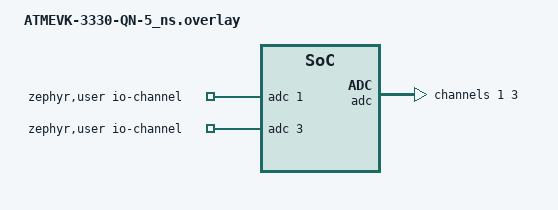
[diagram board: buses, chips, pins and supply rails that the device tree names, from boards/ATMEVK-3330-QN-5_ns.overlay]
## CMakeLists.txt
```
# SPDX-License-Identifier: Apache-2.0

cmake_minimum_required(VERSION 3.28.0)

find_package(Zephyr REQUIRED HINTS $ENV{ZEPHYR_BASE})
project(adc_api)

target_sources(app PRIVATE src/channels.c)
target_sources_ifdef(CONFIG_TEST_ADC_BASIC app PRIVATE src/main.c src/test_adc.c)
target_sources_ifdef(CONFIG_TEST_ADC_ERROR_CASES app PRIVATE src/test_error_cases.c)
target_sources_ifdef(CONFIG_TEST_ADC_ACCURACY_REF app PRIVATE src/test_accuracy_ref.c)
target_sources_ifdef(CONFIG_TEST_ADC_ACCURACY_DAC app PRIVATE src/test_accuracy_dac.c)
```

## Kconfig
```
# ADC API test configuration options

# Copyright (c) 2024 STMicroelectronics
# SPDX-License-Identifier: Apache-2.0

mainmenu "ADC API Test"

source "Kconfig.zephyr"

config ADC_API_SAMPLE_INTERVAL_US
	int "Interval between repeated samples in us"
	default 0

config ADC_32_BITS_DATA
	bool "ADC data is 32-bits long"

config TEST_ADC_CALIBRATE_REQUIRED
	bool "Require calibrate field in ADC test"
	default y if DT_HAS_RENESAS_RA_ADC16_ENABLED
```

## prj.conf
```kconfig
CONFIG_ZTEST=y

CONFIG_ADC=y
CONFIG_ADC_ASYNC=y
CONFIG_ADC_LOG_LEVEL_INF=y
CONFIG_HEAP_MEM_POOL_SIZE=1024
CONFIG_TEST_USERSPACE=y
```

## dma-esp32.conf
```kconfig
#
# Copyright (c) 2024-2025 Espressif Systems (Shanghai) Co., Ltd.
#
# SPDX-License-Identifier: Apache-2.0
#

CONFIG_TEST_USERSPACE=n
CONFIG_ADC_ESP32_DMA=y
CONFIG_HEAP_MEM_POOL_SIZE=16384
```

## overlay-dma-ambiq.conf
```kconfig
CONFIG_ADC_AMBIQ_DMA=y
CONFIG_ADC_ASYNC=n
CONFIG_MAIN_STACK_SIZE=40960
#Reduce the minimum number of samples only for test.
CONFIG_ADC_AMBIQ_DMA_MIN_SAMPLES=2
```

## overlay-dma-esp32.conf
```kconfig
#
# Copyright (c) 2024 Espressif Systems (Shanghai) Co., Ltd.
#
# SPDX-License-Identifier: Apache-2.0
#

CONFIG_TEST_USERSPACE=n
CONFIG_DMA=y
CONFIG_ADC_ESP32_DMA=y
CONFIG_HEAP_MEM_POOL_SIZE=16384
```

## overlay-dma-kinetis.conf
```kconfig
#
# Copyright (c) 2020, NXP
#
# SPDX-License-Identifier: Apache-2.0
#

CONFIG_TEST_USERSPACE=n
CONFIG_ADC_MCUX_ADC16_ENABLE_EDMA=y
CONFIG_ADC_MCUX_ADC16_HW_TRIGGER=y
CONFIG_COUNTER=y
CONFIG_ADC_ASYNC=y
CONFIG_DMA=y
CONFIG_ADC_API_SAMPLE_INTERVAL_US=30000
```

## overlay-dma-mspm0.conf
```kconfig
# SPDX-FileCopyrightText: 2026 Texas Instruments Incorporated
# SPDX-License-Identifier: Apache-2.0

CONFIG_ADC_MSPM0_ADC12_DMA=y
```

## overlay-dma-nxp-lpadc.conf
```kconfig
# Copyright 2025 NXP
# SPDX-License-Identifier: Apache-2.0

CONFIG_ADC_MCUX_LPADC_DMA_DRIVEN=y
CONFIG_TEST_USERSPACE=n
```

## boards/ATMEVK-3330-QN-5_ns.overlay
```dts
/*
 * Copyright (c) 2023 Atmosic
 *
 * SPDX-License-Identifier: Apache-2.0
 */

/ {
	zephyr,user {
		io-channels = <&adc 1>, <&adc 3>;
	};
};

&adc {
	#address-cells = <1>;
	#size-cells = <0>;

	channel@1 {
		reg = <1>;
		zephyr,gain = "ADC_GAIN_1_4";
		zephyr,reference = "ADC_REF_INTERNAL";
		zephyr,acquisition-time = <ADC_ACQ_TIME_DEFAULT>;
		zephyr,resolution = <11>;
	};

	channel@3 {
		reg = <3>;
		zephyr,gain = "ADC_GAIN_1_2";
		zephyr,reference = "ADC_REF_INTERNAL";
		zephyr,acquisition-time = <ADC_ACQ_TIME_DEFAULT>;
		zephyr,resolution = <11>;
	};
};
```

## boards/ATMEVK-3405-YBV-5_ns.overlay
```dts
/*
 * Copyright (c) 2025 Atmosic
 *
 * SPDX-License-Identifier: Apache-2.0
 */

/ {
	zephyr,user {
		io-channels = <&adc 3>, <&adc 4>;
	};
};

&adc {
	#address-cells = <1>;
	#size-cells = <0>;

	channel@1 {
		reg = <1>;
		zephyr,gain = "ADC_GAIN_1_4";
		zephyr,reference = "ADC_REF_INTERNAL";
		zephyr,acquisition-time = <ADC_ACQ_TIME_DEFAULT>;
		zephyr,resolution = <16>;
	};

	channel@2 {
		reg = <2>;
		zephyr,gain = "ADC_GAIN_1_4";
		zephyr,reference = "ADC_REF_INTERNAL";
		zephyr,acquisition-time = <ADC_ACQ_TIME_DEFAULT>;
		zephyr,resolution = <16>;
	};

	channel@3 {
		reg = <3>;
		zephyr,gain = "ADC_GAIN_1_2";
		zephyr,reference = "ADC_REF_INTERNAL";
		zephyr,acquisition-time = <ADC_ACQ_TIME_DEFAULT>;
		zephyr,resolution = <16>;
	};

	channel@4 {
		reg = <4>;
		zephyr,gain = "ADC_GAIN_1";
		zephyr,reference = "ADC_REF_INTERNAL";
		zephyr,acquisition-time = <ADC_ACQ_TIME_DEFAULT>;
		zephyr,resolution = <16>;
	};

	channel@5 {
		reg = <5>;
		zephyr,gain = "ADC_GAIN_1_4";
		zephyr,reference = "ADC_REF_INTERNAL";
		zephyr,acquisition-time = <ADC_ACQ_TIME_DEFAULT>;
		zephyr,resolution = <16>;
	};

	channel@6 {
		reg = <6>;
		zephyr,gain = "ADC_GAIN_1_4";
		zephyr,reference = "ADC_REF_INTERNAL";
		zephyr,acquisition-time = <ADC_ACQ_TIME_DEFAULT>;
		zephyr,resolution = <16>;
	};

	channel@7 {
		reg = <7>;
		zephyr,gain = "ADC_GAIN_1_4";
		zephyr,reference = "ADC_REF_INTERNAL";
		zephyr,acquisition-time = <ADC_ACQ_TIME_DEFAULT>;
		zephyr,resolution = <16>;
	};

	channel@8 {
		reg = <8>;
		zephyr,gain = "ADC_GAIN_1_4";
		zephyr,reference = "ADC_REF_INTERNAL";
		zephyr,acquisition-time = <ADC_ACQ_TIME_DEFAULT>;
		zephyr,resolution = <16>;
	};

	channel@9 {
		reg = <9>;
		zephyr,gain = "ADC_GAIN_1_4";
		zephyr,reference = "ADC_REF_INTERNAL";
		zephyr,acquisition-time = <ADC_ACQ_TIME_DEFAULT>;
		zephyr,resolution = <16>;
	};

	channel@a {
		reg = <10>;
		zephyr,gain = "ADC_GAIN_1_4";
		zephyr,reference = "ADC_REF_INTERNAL";
		zephyr,acquisition-time = <ADC_ACQ_TIME_DEFAULT>;
		zephyr,resolution = <16>;
	};

	channel@b {
		reg = <11>;
		zephyr,gain = "ADC_GAIN_1_2";
		zephyr,reference = "ADC_REF_INTERNAL";
		zephyr,acquisition-time = <ADC_ACQ_TIME_DEFAULT>;
		zephyr,resolution = <16>;
	};
};
```

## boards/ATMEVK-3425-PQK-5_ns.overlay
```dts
/*
 * Copyright (c) 2023 Atmosic
 *
 * SPDX-License-Identifier: Apache-2.0
 */

/ {
	zephyr,user {
		io-channels = <&adc 3>, <&adc 4>;
	};
};

&adc {
	#address-cells = <1>;
	#size-cells = <0>;

	channel@1 {
		reg = <1>;
		zephyr,gain = "ADC_GAIN_1_4";
		zephyr,reference = "ADC_REF_INTERNAL";
		zephyr,acquisition-time = <ADC_ACQ_TIME_DEFAULT>;
		zephyr,resolution = <16>;
	};

	channel@2 {
		reg = <2>;
		zephyr,gain = "ADC_GAIN_1_4";
		zephyr,reference = "ADC_REF_INTERNAL";
		zephyr,acquisition-time = <ADC_ACQ_TIME_DEFAULT>;
		zephyr,resolution = <16>;
	};

	channel@3 {
		reg = <3>;
		zephyr,gain = "ADC_GAIN_1_2";
		zephyr,reference = "ADC_REF_INTERNAL";
		zephyr,acquisition-time = <ADC_ACQ_TIME_DEFAULT>;
		zephyr,resolution = <16>;
	};

	channel@4 {
		reg = <4>;
		zephyr,gain = "ADC_GAIN_1";
		zephyr,reference = "ADC_REF_INTERNAL";
		zephyr,acquisition-time = <ADC_ACQ_TIME_DEFAULT>;
		zephyr,resolution = <16>;
	};

	channel@5 {
		reg = <5>;
		zephyr,gain = "ADC_GAIN_1_4";
		zephyr,reference = "ADC_REF_INTERNAL";
		zephyr,acquisition-time = <ADC_ACQ_TIME_DEFAULT>;
		zephyr,resolution = <16>;
	};

	channel@6 {
		reg = <6>;
		zephyr,gain = "ADC_GAIN_1_4";
		zephyr,reference = "ADC_REF_INTERNAL";
		zephyr,acquisition-time = <ADC_ACQ_TIME_DEFAULT>;
		zephyr,resolution = <16>;
	};

	channel@7 {
		reg = <7>;
		zephyr,gain = "ADC_GAIN_1_4";
		zephyr,reference = "ADC_REF_INTERNAL";
		zephyr,acquisition-time = <ADC_ACQ_TIME_DEFAULT>;
		zephyr,resolution = <16>;
	};

	channel@8 {
		reg = <8>;
		zephyr,gain = "ADC_GAIN_1_4";
		zephyr,reference = "ADC_REF_INTERNAL";
		zephyr,acquisition-time = <ADC_ACQ_TIME_DEFAULT>;
		zephyr,resolution = <16>;
	};

	channel@9 {
		reg = <9>;
		zephyr,gain = "ADC_GAIN_1_4";
		zephyr,reference = "ADC_REF_INTERNAL";
		zephyr,acquisition-time = <ADC_ACQ_TIME_DEFAULT>;
		zephyr,resolution = <16>;
	};

	channel@a {
		reg = <10>;
		zephyr,gain = "ADC_GAIN_1_4";
		zephyr,reference = "ADC_REF_INTERNAL";
		zephyr,acquisition-time = <ADC_ACQ_TIME_DEFAULT>;
		zephyr,resolution = <16>;
	};

	channel@b {
		reg = <11>;
		zephyr,gain = "ADC_GAIN_1_2";
		zephyr,reference = "ADC_REF_INTERNAL";
		zephyr,acquisition-time = <ADC_ACQ_TIME_DEFAULT>;
		zephyr,resolution = <16>;
	};
};
```

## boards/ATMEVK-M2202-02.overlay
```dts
/*
 * Copyright (c) 2023 Atmosic
 *
 * SPDX-License-Identifier: Apache-2.0
 */

/ {
	zephyr,user {
		io-channels = <&adc 0>, <&adc 2>;
	};
};

&adc {
	#address-cells = <1>;
	#size-cells = <0>;

	channel@0 {
		reg = <0>;
		zephyr,gain = "ADC_GAIN_1";
		zephyr,reference = "ADC_REF_INTERNAL";
		zephyr,acquisition-time = <ADC_ACQ_TIME_DEFAULT>;
		zephyr,resolution = <10>;
	};

	channel@2 {
		reg = <2>;
		zephyr,gain = "ADC_GAIN_1";
		zephyr,reference = "ADC_REF_INTERNAL";
		zephyr,acquisition-time = <ADC_ACQ_TIME_DEFAULT>;
		zephyr,resolution = <10>;
	};
};
```

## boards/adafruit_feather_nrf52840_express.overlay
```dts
/*
 * SPDX-License-Identifier: Apache-2.0
 *
 * Copyright (c) 2023 Benjamin Björnsson <benjamin.bjornsson@gmail.com>
 */

#include "nordic,nrf-saadc-common.dtsi"
```

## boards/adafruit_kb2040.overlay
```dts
/*
 * Copyright (c) 2023 Benjamin Björnsson <benjamin.bjornsson@gmail.com>
 *
 * SPDX-License-Identifier: Apache-2.0
 */

#include <zephyr/dt-bindings/adc/adc.h>

/ {
	zephyr,user {
		io-channels = <&adc 0>, <&adc 1>;
	};
};

&adc {
	#address-cells = <1>;
	#size-cells = <0>;

	channel@0 {
		reg = <0>;
		zephyr,gain = "ADC_GAIN_1";
		zephyr,reference = "ADC_REF_INTERNAL";
		zephyr,acquisition-time = <ADC_ACQ_TIME_DEFAULT>;
		zephyr,resolution = <12>;
	};

	channel@1 {
		reg = <1>;
		zephyr,gain = "ADC_GAIN_1";
		zephyr,reference = "ADC_REF_INTERNAL";
		zephyr,acquisition-time = <ADC_ACQ_TIME_DEFAULT>;
		zephyr,resolution = <12>;
	};
};
```

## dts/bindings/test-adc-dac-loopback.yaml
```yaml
# SPDX-FileCopyrightText: Copyright The Zephyr Project Contributors
# SPDX-License-Identifier: Apache-2.0

description: |
  A DAC output of the board wired to one of its ADC channels, for the
  accuracy test of tests/drivers/adc/adc_api.

compatible: "test-adc-dac-loopback"

include: base.yaml

properties:
  io-channels:
    type: phandle-array
    required: true
    description: The ADC channel the DAC output is wired to.

  dac:
    type: phandle
    required: true
    description: The DAC controller.

  dac-channel-id:
    type: int
    required: true
    description: The DAC channel driving the output.

  dac-resolution:
    type: int
    required: true
    description: The resolution the DAC channel is set up with, in bits.
```

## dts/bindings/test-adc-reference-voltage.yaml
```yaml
# SPDX-FileCopyrightText: Copyright The Zephyr Project Contributors
# SPDX-License-Identifier: Apache-2.0

description: |
  A known voltage wired to an ADC channel of the board, for the accuracy
  test of tests/drivers/adc/adc_api.

compatible: "test-adc-reference-voltage"

include: base.yaml

properties:
  io-channels:
    type: phandle-array
    required: true
    description: The ADC channel the reference voltage is wired to.

  reference-mv:
    type: int
    required: true
    description: The reference voltage, in millivolts.

  expected-accuracy:
    type: int
    required: true
    description: The largest acceptable difference from the reference, in millivolts.
```

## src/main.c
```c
/*
 * Copyright (c) 2018 Nordic Semiconductor ASA
 * Copyright (c) 2016 Intel Corporation
 *
 * SPDX-License-Identifier: Apache-2.0
 */


#include <zephyr/kernel.h>
#include <zephyr/ztest.h>

#include "adc_test.h"

extern struct k_poll_signal async_sig;

void *adc_basic_setup(void)
{
	k_object_access_grant(get_adc_device(), k_current_get());
#ifdef CONFIG_ADC_ASYNC
	k_object_access_grant(&async_sig, k_current_get());
	k_poll_signal_init(&async_sig);
	k_thread_system_pool_assign(k_current_get());
#endif

	return NULL;
}

ZTEST_SUITE(adc_basic, NULL, adc_basic_setup, NULL, NULL, NULL);
```

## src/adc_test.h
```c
/*
 * SPDX-FileCopyrightText: Copyright The Zephyr Project Contributors
 * SPDX-License-Identifier: Apache-2.0
 */

#ifndef TESTS_DRIVERS_ADC_ADC_API_SRC_ADC_TEST_H_
#define TESTS_DRIVERS_ADC_ADC_API_SRC_ADC_TEST_H_

#include <zephyr/drivers/adc.h>

#define ADC_TEST_COUNT_ONE(node_id) + 1

/*
 * Number of channels the board makes available to the tests: the io-channels
 * of the zephyr,user node when present, otherwise every channel node of an
 * enabled ADC controller.
 */
#if DT_NODE_HAS_PROP(DT_PATH(zephyr_user), io_channels)
#define ADC_TEST_CHANNEL_COUNT DT_PROP_LEN(DT_PATH(zephyr_user), io_channels)
#else
#define ADC_TEST_CHANNEL_COUNT (0 ADC_DT_FOREACH_CHANNEL_NODE(ADC_TEST_COUNT_ONE))
#endif

BUILD_ASSERT(ADC_TEST_CHANNEL_COUNT > 0, "No ADC channel described in devicetree");

/* The channels, the first one being the one the tests exercise. */
extern const struct adc_dt_spec adc_test_channels[ADC_TEST_CHANNEL_COUNT];

/* The controller of the first channel, or NULL when it is not ready. */
const struct device *get_adc_device(void);

#endif /* TESTS_DRIVERS_ADC_ADC_API_SRC_ADC_TEST_H_ */
```

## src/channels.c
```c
/*
 * SPDX-FileCopyrightText: Copyright The Zephyr Project Contributors
 * SPDX-License-Identifier: Apache-2.0
 */

#include <zephyr/drivers/adc.h>
#include <zephyr/sys/printk.h>

#include "adc_test.h"

#define DT_SPEC_AND_COMMA(node_id, prop, idx) ADC_DT_SPEC_GET_BY_IDX(node_id, idx),
#define CHANNEL_NODE_SPEC_AND_COMMA(node_id) ADC_DT_SPEC_FROM_CHANNEL_NODE(node_id),

const struct adc_dt_spec adc_test_channels[ADC_TEST_CHANNEL_COUNT] = {
#if DT_NODE_HAS_PROP(DT_PATH(zephyr_user), io_channels)
	DT_FOREACH_PROP_ELEM(DT_PATH(zephyr_user), io_channels, DT_SPEC_AND_COMMA)
#else
	ADC_DT_FOREACH_CHANNEL_NODE(CHANNEL_NODE_SPEC_AND_COMMA)
#endif
};

const struct device *get_adc_device(void)
{
	if (!adc_is_ready_dt(&adc_test_channels[0])) {
		printk("ADC device is not ready\n");
		return NULL;
	}

	return adc_test_channels[0].dev;
}
```

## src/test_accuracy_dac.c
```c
/*
 * Copyright (c) 2023 Intel Corporation
 *
 * SPDX-License-Identifier: Apache-2.0
 */

#include <zephyr/drivers/adc.h>
#include <zephyr/drivers/dac.h>
#include <zephyr/ztest.h>

#define DIV 2

/* The board's DAC output and the ADC channel it is wired to. */
#define DAC_NODE DT_COMPAT_GET_ANY_STATUS_OKAY(test_adc_dac_loopback)
#define DAC_DEVICE_NODE	DT_PROP(DAC_NODE, dac)
#define DAC_CHANNEL_ID DT_PROP(DAC_NODE, dac_channel_id)

static const struct adc_dt_spec adc_channel = ADC_DT_SPEC_GET(DAC_NODE);

static const struct dac_channel_cfg dac_ch_cfg = {
	.channel_id = DAC_CHANNEL_ID,
	.resolution = DT_PROP(DAC_NODE, dac_resolution),
	.buffered = !IS_ENABLED(CONFIG_TEST_DAC_BUFFER_NOT_SUPPORTED),
};

static const struct device *init_dac(void)
{
	int ret;
	const struct device *const dac_dev = DEVICE_DT_GET(DAC_DEVICE_NODE);

	zassert_true(device_is_ready(dac_dev), "DAC device is not ready");

	ret = dac_channel_setup(dac_dev, &dac_ch_cfg);
	zassert_equal(ret, 0,
		      "Setting up of the first channel failed with code %d", ret);

	return dac_dev;
}

static int test_dac_to_adc(void)
{
	int ret, write_val;
	int32_t sample_buffer = 0;

	struct adc_sequence sequence = {
		.buffer      = &sample_buffer,
		.buffer_size = sizeof(sample_buffer),
#if CONFIG_TEST_ADC_CALIBRATE_REQUIRED
		.calibrate = true,
#endif
	};

	const struct device *dac_dev = init_dac();

	write_val = (1U << dac_ch_cfg.resolution) / DIV;

	ret = dac_write_value(dac_dev, DAC_CHANNEL_ID, write_val);

	zassert_equal(ret, 0, "dac_write_value() failed with code %d", ret);

	k_sleep(K_MSEC(10));

	adc_sequence_init_dt(&adc_channel, &sequence);
	ret = adc_read_dt(&adc_channel, &sequence);

	zassert_equal(ret, 0, "adc_read_dt() failed with code %d", ret);
	zassert_within(sample_buffer,
			(1U << adc_channel.resolution) / DIV, 32,
			"Value %d read from ADC does not match expected range.",
			sample_buffer);

	return TC_PASS;
}

ZTEST(adc_accuracy_dac, test_dac_to_adc)
{
	int i;

	for (i = 0; i < CONFIG_TEST_ADC_ACCURACY_PASSES; i++) {
		zassert_true(test_dac_to_adc() == TC_PASS);
	}
}

static void *adc_setup(void)
{
	int ret;

	zassert_true(adc_is_ready_dt(&adc_channel), "ADC device is not ready");
	ret = adc_channel_setup_dt(&adc_channel);
	zassert_equal(ret, 0,
		"Setting up of the ADC channel failed with code %d", ret);

	return NULL;
}

ZTEST_SUITE(adc_accuracy_dac, NULL, adc_setup, NULL, NULL, NULL);
```

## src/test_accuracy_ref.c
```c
/*
 * Copyright (c) 2023 Intel Corporation
 *
 * SPDX-License-Identifier: Apache-2.0
 */

#include <zephyr/drivers/adc.h>
#include <zephyr/ztest.h>

/* The board's known voltage and the channel it is wired to. */
#define REF_NODE DT_COMPAT_GET_ANY_STATUS_OKAY(test_adc_reference_voltage)
#define REF_V DT_PROP(REF_NODE, reference_mv)
#define EXP_ACC DT_PROP(REF_NODE, expected_accuracy)

static const struct adc_dt_spec adc_channel = ADC_DT_SPEC_GET(REF_NODE);

static int test_ref_to_adc(void)
{
	int ret;
	int32_t sample_buffer = 0;

	struct adc_sequence sequence = {
		.buffer      = &sample_buffer,
		.buffer_size = sizeof(sample_buffer),
		.calibrate = true,
	};

	adc_sequence_init_dt(&adc_channel, &sequence);

	ret = adc_read_dt(&adc_channel, &sequence);
	zassert_equal(ret, 0, "adc_read_dt() failed with code %d", ret);

	ret = adc_raw_to_millivolts_dt(&adc_channel, &sample_buffer);
	zassert_equal(ret, 0, "adc_raw_to_millivolts_dt() failed with code %d",
		      ret);
	zassert_within(sample_buffer, REF_V, EXP_ACC,
		"Value %d mV read from ADC does not match expected range (%d mV).",
		sample_buffer, REF_V);

	return TC_PASS;
}

ZTEST(adc_accuracy_ref, test_ref_to_adc)
{
	int i;

	for (i = 0; i < CONFIG_TEST_ADC_ACCURACY_PASSES; i++) {
		zassert_true(test_ref_to_adc() == TC_PASS);
	}
}

static void *adc_setup(void)
{
	int ret;

	zassert_true(adc_is_ready_dt(&adc_channel), "ADC device is not ready");
	ret = adc_channel_setup_dt(&adc_channel);
	zassert_equal(ret, 0,
		"Setting up of the ADC channel failed with code %d", ret);

	return NULL;
}

ZTEST_SUITE(adc_accuracy_ref, NULL, adc_setup, NULL, NULL, NULL);
```

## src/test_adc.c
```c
/*
 * Copyright (c) 2018 Nordic Semiconductor ASA
 * Copyright (c) 2016 Intel Corporation
 *
 * SPDX-License-Identifier: Apache-2.0
 */


#include <zephyr/drivers/adc.h>
#include <zephyr/drivers/dma.h>
#include <zephyr/drivers/counter.h>
#include <zephyr/kernel.h>
#include <zephyr/ztest.h>

#if CONFIG_ADC_32_BITS_DATA
typedef int32_t adc_data_size_t;
#define INVALID_ADC_VALUE INT_MIN
#else
typedef int16_t adc_data_size_t;
#endif

/* Invalid value that is not supposed to be written by the driver. It is used
 * to mark the sample buffer entries as empty. If needed, it can be overridden
 * for a particular board by providing a specific definition above.
 */
#if !defined(INVALID_ADC_VALUE)
#define INVALID_ADC_VALUE SHRT_MIN
#endif

#if CONFIG_NOCACHE_MEMORY
#define __NOCACHE	__attribute__((__section__(".nocache")))
#else /* CONFIG_NOCACHE_MEMORY */
#define __NOCACHE
#endif /* CONFIG_NOCACHE_MEMORY */

#define BUFFER_SIZE  15
#ifdef CONFIG_TEST_USERSPACE
static ZTEST_BMEM adc_data_size_t m_sample_buffer[BUFFER_SIZE];
#else
static __aligned(32) adc_data_size_t m_sample_buffer[BUFFER_SIZE] __NOCACHE;
#endif

#define DT_SPEC_AND_COMMA(node_id, prop, idx)	ADC_DT_SPEC_GET_BY_IDX(node_id, idx),

#if DT_NODE_HAS_PROP(DT_PATH(zephyr_user), io_channels)
/* Data of ADC io-channels specified in devicetree. */
static const struct adc_dt_spec adc_channels[] = {
	DT_FOREACH_PROP_ELEM(DT_PATH(zephyr_user), io_channels, DT_SPEC_AND_COMMA)
};
static const int adc_channels_count = ARRAY_SIZE(adc_channels);
#else
#error "Unsupported board."
#endif

#ifdef CONFIG_ADC_SEQUENCE_PRIORITY
static const struct adc_dt_spec adc_channels_prio0[] = {
	DT_FOREACH_PROP_ELEM(DT_PATH(zephyr_user), prio0_io_channels, DT_SPEC_AND_COMMA)
};
static const struct adc_dt_spec adc_channels_prio1[] = {
	DT_FOREACH_PROP_ELEM(DT_PATH(zephyr_user), prio1_io_channels, DT_SPEC_AND_COMMA)
};
static const int adc_channels_prio0_count = ARRAY_SIZE(adc_channels_prio0);
static const int adc_channels_prio1_count = ARRAY_SIZE(adc_channels_prio1);

#define PRIO0_BUFFER_SIZE	60
#define PRIO1_BUFFER_SIZE	3

#ifdef CONFIG_TEST_USERSPACE
static ZTEST_BMEM adc_data_size_t m_prio0_sample_buffer[PRIO0_BUFFER_SIZE];
static ZTEST_BMEM adc_data_size_t m_prio1_sample_buffer[PRIO1_BUFFER_SIZE];
#else /* CONFIG_TEST_USERSPACE */
static __aligned(32) adc_data_size_t m_prio0_sample_buffer[PRIO0_BUFFER_SIZE] __NOCACHE;
static __aligned(32) adc_data_size_t m_prio1_sample_buffer[PRIO1_BUFFER_SIZE] __NOCACHE;
#endif /* CONFIG_TEST_USERSPACE */
#endif /* CONFIG_ADC_SEQUENCE_PRIORITY */

const struct device *get_adc_device(void)
{
	if (!adc_is_ready_dt(&adc_channels[0])) {
		printk("ADC device is not ready\n");
		return NULL;
	}

	return adc_channels[0].dev;
}

#if DT_NODE_HAS_STATUS_OKAY(DT_NODELABEL(test_counter)) && \
	defined(CONFIG_COUNTER)
static void init_counter(void)
{
	int err;
	const struct device *const dev = DEVICE_DT_GET(DT_NODELABEL(test_counter));
	struct counter_top_cfg top_cfg = { .callback = NULL,
					   .user_data = NULL,
					   .flags = 0 };

	zassert_true(device_is_ready(dev), "Counter device is not ready");

	counter_start(dev);
	top_cfg.ticks = counter_us_to_ticks(dev, CONFIG_ADC_API_SAMPLE_INTERVAL_US);
	err = counter_set_top_value(dev, &top_cfg);
	zassert_equal(0, err, "%s: Counter failed to set top value (err: %d)",
		      dev->name, err);
}
#endif

static void init_adc(void)
{
	int i, ret;

	zassert_true(adc_is_ready_dt(&adc_channels[0]), "ADC device is not ready");

	for (i = 0; i < adc_channels_count; i++) {
		ret = adc_channel_setup_dt(&adc_channels[i]);
		zassert_equal(ret, 0, "Setting up of channel %d failed with code %d", i, ret);
	}

	for (i = 0; i < BUFFER_SIZE; ++i) {
		m_sample_buffer[i] = INVALID_ADC_VALUE;
	}

#ifdef CONFIG_ADC_SEQUENCE_PRIORITY
	for (i = 0; i < PRIO1_BUFFER_SIZE; ++i) {
		m_prio1_sample_buffer[i] = INVALID_ADC_VALUE;
	}

	for (i = 0; i < PRIO0_BUFFER_SIZE; ++i) {
		m_prio0_sample_buffer[i] = INVALID_ADC_VALUE;
	}
#endif /* CONFIG_ADC_SEQUENCE_PRIORITY */

#if DT_NODE_HAS_STATUS_OKAY(DT_NODELABEL(test_counter)) && \
	defined(CONFIG_COUNTER)
	init_counter();
#endif
}

static void check_samples(int expected_count, adc_data_size_t *sample_buffer, size_t buffer_size)
{
	int i;

	TC_PRINT("Samples read: ");
	for (i = 0; i < buffer_size; i++) {
		adc_data_size_t sample_value = sample_buffer[i];

#if CONFIG_ADC_32_BITS_DATA
		TC_PRINT("0x%08x ", sample_value);
#else
		TC_PRINT("0x%04hx ", sample_value);
#endif
		if (i < expected_count) {
			zassert_not_equal(INVALID_ADC_VALUE, sample_value,
				"[%u] should be filled", i);
		} else {
			zassert_equal(INVALID_ADC_VALUE, sample_value,
				"[%u] should be empty", i);
		}
	}
	TC_PRINT("\n");
}

/*
 * test_adc_sample_one_channel
 */
static int test_task_one_channel(void)
{
	int ret;
	struct adc_sequence sequence = {
		.buffer = m_sample_buffer,
		.buffer_size = sizeof(m_sample_buffer),
#if CONFIG_TEST_ADC_CALIBRATE_REQUIRED
		.calibrate = true,
#endif
	};

	init_adc();
	(void)adc_sequence_init_dt(&adc_channels[0], &sequence);

	ret = adc_read_dt(&adc_channels[0], &sequence);
	zassert_equal(ret, 0, "adc_read() failed with code %d", ret);

	check_samples(1, m_sample_buffer, BUFFER_SIZE);

	return TC_PASS;
}

ZTEST_USER(adc_basic, test_adc_sample_one_channel)
{
	zassert_true(test_task_one_channel() == TC_PASS);
}

/*
 * test_adc_sample_invalid_buffer
 */
static int test_task_invalid_buffer(void)
{
	int ret;
	uint8_t small_buffer[2];

	struct adc_sequence sequence = {
		.buffer = small_buffer,
		.buffer_size = sizeof(small_buffer) - 1,
#if CONFIG_TEST_ADC_CALIBRATE_REQUIRED
		.calibrate = true,
#endif
	};

	small_buffer[1] = UINT8_MAX;

	init_adc();
	(void)adc_sequence_init_dt(&adc_channels[0], &sequence);

	ret = adc_read_dt(&adc_channels[0], &sequence);
	zassert_equal(ret, -ENOMEM, "adc_read() incorrectly returned with code %d", ret);
	zassert_equal(small_buffer[1], UINT8_MAX, "adc_read() overwrote beyond the buffer size");

	return TC_PASS;
}

ZTEST_USER(adc_basic, test_adc_sample_invalid_buffer)
{
	zassert_true(test_task_invalid_buffer() == TC_PASS);
}

/*
 * test_adc_sample_multiple_channels
 */
static int test_task_multiple_channels(void)
{
	int ret;
	struct adc_sequence sequence = {
		.buffer      = m_sample_buffer,
		.buffer_size = sizeof(m_sample_buffer),
#if CONFIG_TEST_ADC_CALIBRATE_REQUIRED
		.calibrate = true,
#endif
	};

	init_adc();
	(void)adc_sequence_init_dt(&adc_channels[0], &sequence);

	for (int i = 1; i < adc_channels_count; i++) {
		sequence.channels |= BIT(adc_channels[i].channel_id);
	}

	ret = adc_read_dt(&adc_channels[0], &sequence);
	if (ret == -ENOTSUP) {
		ztest_test_skip();
	}
	zassert_equal(ret, 0, "adc_read() failed with code %d", ret);

	check_samples(adc_channels_count, m_sample_buffer, BUFFER_SIZE);

	return TC_PASS;
}

ZTEST_USER(adc_basic, test_adc_sample_two_channels)
{
	if (adc_channels_count > 1) {
		zassert_true(test_task_multiple_channels() == TC_PASS);
	} else {
		ztest_test_skip();
	}
}

/*
 * test_adc_asynchronous_call
 */
#if defined(CONFIG_ADC_ASYNC)
struct k_poll_signal async_sig;

static int test_task_asynchronous_call(void)
{
	int ret;
	const struct adc_sequence_options options = {
		.extra_samplings = 4,
		/* Start consecutive samplings as fast as possible. */
		.interval_us     = CONFIG_ADC_API_SAMPLE_INTERVAL_US,
	};
	struct adc_sequence sequence = {
		.options     = &options,
		.buffer      = m_sample_buffer,
		.buffer_size = sizeof(m_sample_buffer),
#if CONFIG_TEST_ADC_CALIBRATE_REQUIRED
		.calibrate = true,
#endif
	};
	struct k_poll_event  async_evt =
		K_POLL_EVENT_INITIALIZER(K_POLL_TYPE_SIGNAL,
					 K_POLL_MODE_NOTIFY_ONLY,
					 &async_sig);
	init_adc();

	(void)adc_sequence_init_dt(&adc_channels[0], &sequence);

	ret = adc_read_async(adc_channels[0].dev, &sequence, &async_sig);
	zassert_equal(ret, 0, "adc_read_async() failed with code %d", ret);

	ret = k_poll(&async_evt, 1, K_MSEC(1000));
	zassert_equal(ret, 0, "k_poll failed with error %d", ret);

	check_samples(1 + options.extra_samplings, m_sample_buffer, BUFFER_SIZE);

	return TC_PASS;
}

#if defined(CONFIG_ADC_SEQUENCE_PRIORITY)
static int test_task_different_priorities_sequences(void)
{
	int ret;
	const struct adc_sequence_options options = {
		.extra_samplings = 4,
		/* Start consecutive samplings as fast as possible. */
		.interval_us     = CONFIG_ADC_API_SAMPLE_INTERVAL_US,
	};
	struct adc_sequence prio0_sequence = {
		.options     = &options,
		.buffer      = m_prio0_sample_buffer,
		.buffer_size = PRIO0_BUFFER_SIZE * sizeof(adc_data_size_t),
		.priority    = 0U,
	};
	struct adc_sequence prio1_sequence = {
		.buffer      = m_prio1_sample_buffer,
		.buffer_size = PRIO1_BUFFER_SIZE * sizeof(adc_data_size_t),
		.priority    = 1U,
	};
	struct k_poll_event async_evt = K_POLL_EVENT_INITIALIZER(K_POLL_TYPE_SIGNAL,
								 K_POLL_MODE_NOTIFY_ONLY,
								 &async_sig);

	init_adc();

	(void)adc_sequence_init_dt(&adc_channels_prio0[0], &prio0_sequence);

	for (int i = 1; i < adc_channels_prio0_count; i++) {
		prio0_sequence.channels |= BIT(adc_channels_prio0[i].channel_id);
	}

	(void)adc_sequence_init_dt(&adc_channels_prio1[0], &prio1_sequence);

	for (int i = 1; i < adc_channels_prio1_count; i++) {
		prio1_sequence.channels |= BIT(adc_channels_prio1[i].channel_id);
	}

	ret = adc_read_async_dt(&adc_channels_prio0[0], &prio0_sequence, &async_sig);
	zassert_equal(ret, 0, "adc_read_async() failed with code %d", ret);

	ret = adc_read_dt(&adc_channels_prio1[0], &prio1_sequence);
	zassert_equal(ret, 0, "adc_read_dt() failed with code %d", ret);

	check_samples(adc_channels_prio1_count, m_prio1_sample_buffer, PRIO1_BUFFER_SIZE);

	ret = k_poll(&async_evt, 1, K_MSEC(1000));
	zassert_equal(ret, 0, "k_poll failed with error %d", ret);

	check_samples(adc_channels_prio0_count * (options.extra_samplings + 1),
		      m_prio0_sample_buffer, PRIO0_BUFFER_SIZE);

	return TC_PASS;
}
#endif /* defined(CONFIG_ADC_SEQUENCE_PRIORITY) */
#endif /* defined(CONFIG_ADC_ASYNC) */

ZTEST_USER(adc_basic, test_adc_asynchronous_call)
{
#if defined(CONFIG_ADC_ASYNC)
	zassert_true(test_task_asynchronous_call() == TC_PASS);
#else
	ztest_test_skip();
#endif /* defined(CONFIG_ADC_ASYNC) */
}

ZTEST_USER(adc_basic, test_task_different_priorities_sequences)
{
#if defined(CONFIG_ADC_ASYNC) && defined(CONFIG_ADC_SEQUENCE_PRIORITY)
	zassert_true(test_task_different_priorities_sequences() == TC_PASS);
#else
	ztest_test_skip();
#endif /* defined(CONFIG_ADC_ASYNC) && defined(CONFIG_ADC_SEQUENCE_PRIORITY) */
}

/*
 * test_adc_sample_with_interval
 */
static uint32_t my_sequence_identifier = 0x12345678;
static void *user_data = &my_sequence_identifier;

static enum adc_action sample_with_interval_callback(const struct device *dev,
						     const struct adc_sequence *sequence,
						     uint16_t sampling_index)
{
	if (sequence->options->user_data != &my_sequence_identifier) {
		user_data = sequence->options->user_data;
		return ADC_ACTION_FINISH;
	}

	TC_PRINT("%s: sampling %d\n", __func__, sampling_index);
	return ADC_ACTION_CONTINUE;
}

static int test_task_with_interval(void)
{
	int ret;
	const struct adc_sequence_options options = {
		.interval_us     = 100 * 1000UL,
		.callback        = sample_with_interval_callback,
		.user_data       = user_data,
		.extra_samplings = 4,
	};
	struct adc_sequence sequence = {
		.options     = &options,
		.buffer      = m_sample_buffer,
		.buffer_size = sizeof(m_sample_buffer),
#if CONFIG_TEST_ADC_CALIBRATE_REQUIRED
		.calibrate = true,
#endif
	};

	init_adc();

	(void)adc_sequence_init_dt(&adc_channels[0], &sequence);

	ret = adc_read_dt(&adc_channels[0], &sequence);
	if (ret == -ENOTSUP) {
		ztest_test_skip();
	}
	zassert_equal(ret, 0, "adc_read() failed with code %d", ret);

	zassert_equal(user_data, sequence.options->user_data,
		"Invalid user data: %p, expected: %p",
		user_data, sequence.options->user_data);

	check_samples(1 + options.extra_samplings, m_sample_buffer, BUFFER_SIZE);

	return TC_PASS;
}

ZTEST(adc_basic, test_adc_sample_with_interval)
{
	zassert_true(test_task_with_interval() == TC_PASS);
}

/*
 * test_adc_repeated_samplings
 */
static uint8_t m_samplings_done;
static enum adc_action repeated_samplings_callback(const struct device *dev,
						   const struct adc_sequence *sequence,
						   uint16_t sampling_index)
{
	++m_samplings_done;
	TC_PRINT("%s: done %d\n", __func__, m_samplings_done);
	if (m_samplings_done == 1U) {
		check_samples(MIN(adc_channels_count, 2), m_sample_buffer, BUFFER_SIZE);

		/* After first sampling continue normally. */
		return ADC_ACTION_CONTINUE;
	} else {
		check_samples(2 * MIN(adc_channels_count, 2), m_sample_buffer, BUFFER_SIZE);

		/*
		 * The second sampling is repeated 9 times (the samples are
		 * written in the same place), then the sequence is finished
		 * prematurely.
		 */
		if (m_samplings_done < 10) {
			return ADC_ACTION_REPEAT;
		} else {
			return ADC_ACTION_FINISH;
		}
	}
}

static int test_task_repeated_samplings(void)
{
	int ret;
	const struct adc_sequence_options options = {
		.callback        = repeated_samplings_callback,
		/*
		 * This specifies that 3 samplings are planned. However,
		 * the callback function above is constructed in such way
		 * that the first sampling is done normally, the second one
		 * is repeated 9 times, and then the sequence is finished.
		 * Hence, the third sampling will not take place.
		 */
		.extra_samplings = 2,
		/* Start consecutive samplings as fast as possible. */
		.interval_us     = CONFIG_ADC_API_SAMPLE_INTERVAL_US,
	};
	struct adc_sequence sequence = {
		.options     = &options,
		.buffer      = m_sample_buffer,
		.buffer_size = sizeof(m_sample_buffer),
#if CONFIG_TEST_ADC_CALIBRATE_REQUIRED
		.calibrate = true,
#endif
	};

	init_adc();
	(void)adc_sequence_init_dt(&adc_channels[0], &sequence);

	if (adc_channels_count > 1) {
		sequence.channels |=  BIT(adc_channels[1].channel_id);
	}

	ret = adc_read_dt(&adc_channels[0], &sequence);
	if (ret == -ENOTSUP) {
		ztest_test_skip();
	}
	zassert_equal(ret, 0, "adc_read() failed with code %d", ret);

	return TC_PASS;
}

ZTEST(adc_basic, test_adc_repeated_samplings)
{
	zassert_true(test_task_repeated_samplings() == TC_PASS);
}

/*
 * test_adc_invalid_request
 */
static int test_task_invalid_request(void)
{
	int ret;
	struct adc_sequence sequence = {
		.channels    = BIT(adc_channels[0].channel_id),
		.buffer      = m_sample_buffer,
		.buffer_size = sizeof(m_sample_buffer),
		.resolution  = 0, /* intentionally invalid value */
#if CONFIG_TEST_ADC_CALIBRATE_REQUIRED
		.calibrate = true,
#endif
	};

	init_adc();

	ret = adc_read_dt(&adc_channels[0], &sequence);
	zassert_not_equal(ret, 0, "adc_read() unexpectedly succeeded");

#if defined(CONFIG_ADC_ASYNC)
	ret = adc_read_async(adc_channels[0].dev, &sequence, &async_sig);
	zassert_not_equal(ret, 0, "adc_read_async() unexpectedly succeeded");
#endif

	/*
	 * Make the sequence parameters valid, now the request should succeed.
	 */
	sequence.resolution = adc_channels[0].resolution;

	ret = adc_read_dt(&adc_channels[0], &sequence);
	zassert_equal(ret, 0, "adc_read() failed with code %d", ret);

	check_samples(1, m_sample_buffer, BUFFER_SIZE);

	return TC_PASS;
}

ZTEST_USER(adc_basic, test_adc_invalid_request)
{
	zassert_true(test_task_invalid_request() == TC_PASS);
}
```

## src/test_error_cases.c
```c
/*
 * Copyright (c) 2024, Nordic Semiconductor ASA
 *
 * SPDX-License-Identifier: Apache-2.0
 */

#include <zephyr/kernel.h>
#include <zephyr/device.h>
#include <zephyr/ztest.h>
#include <zephyr/drivers/adc.h>

#include "adc_test.h"

#define BUFFER_LEN 8
static uint16_t m_sample_buffer[BUFFER_LEN];

/* A channel the board describes, and a channel id it does not. */
#define VALID_CHANNEL (&adc_test_channels[0])
static uint8_t unused_channel_id;

static struct adc_sequence valid_seq = {
	.buffer = m_sample_buffer,
	.buffer_size = BUFFER_LEN * sizeof(m_sample_buffer),
	.options = NULL,
	.oversampling = 0,
};

/**
 * @brief test adc_read() with invalid oversampling value
 *
 * function should return -EINVAL
 */

ZTEST(adc_error_cases, test_adc_read_invalid_oversampling)
{
	int ret;

	adc_channel_setup_dt(VALID_CHANNEL);

	struct adc_sequence invalid_seq = valid_seq;
	/* Set oversampling to invalid value */
	invalid_seq.oversampling = 99;

	ret = adc_read_dt(VALID_CHANNEL, &invalid_seq);

	zassert_true(
		ret == -EINVAL,
		"adc_read() should return -EINVAL,"
		" got unexpected value of %d",
		ret
	);
}

/**
 * @brief test adc_read() with invalid resolution value
 *
 * function should return -EINVAL
 */

ZTEST(adc_error_cases, test_adc_read_invalid_resolution)
{
	int ret;

	adc_channel_setup_dt(VALID_CHANNEL);

	struct adc_sequence invalid_seq = valid_seq;
	/* Set resolution to invalid value */
	invalid_seq.resolution = 99;

	ret = adc_read_dt(VALID_CHANNEL, &invalid_seq);

	zassert_true(
		ret == -EINVAL,
		"adc_read() should return -EINVAL,"
		" got unexpected value of %d",
		ret
	);
}

/**
 * @brief test adc_read() with invalid channels value
 *
 * function should return -EINVAL
 */

ZTEST(adc_error_cases, test_adc_read_invalid_channels)
{
	int ret;

	adc_channel_setup_dt(VALID_CHANNEL);

	struct adc_sequence invalid_seq = valid_seq;
	/* Set channels configuration to invalid value */
	invalid_seq.channels = 0;

	ret = adc_read_dt(VALID_CHANNEL, &invalid_seq);

	zassert_true(
		ret == -EINVAL,
		"adc_read() should return -EINVAL,"
		" got unexpected value of %d",
		ret
	);
}

/**
 * @brief test adc_read() with not configured channel
 *
 * function should return -EINVAL
 */

ZTEST(adc_error_cases, test_adc_read_not_configured_channel)
{
	int ret;

	adc_channel_setup_dt(VALID_CHANNEL);

	struct adc_sequence invalid_seq = valid_seq;
	/* Set channels configuration to use not configured channel */
	invalid_seq.channels = BIT(unused_channel_id);

	ret = adc_read_dt(VALID_CHANNEL, &invalid_seq);

	zassert_true(
		ret == -EINVAL,
		"adc_read() should return -EINVAL,"
		" got unexpected value of %d",
		ret
	);
}

/**
 * @brief test adc_read() with invalid buffer length
 *
 * function should return -ENOMEM
 */

ZTEST(adc_error_cases, test_adc_read_invalid_buffer)
{
	int ret;

	adc_channel_setup_dt(VALID_CHANNEL);

	struct adc_sequence invalid_seq = valid_seq;
	/* set buffer size to 0 bytes */
	invalid_seq.buffer_size = 0;

	ret = adc_read_dt(VALID_CHANNEL, &invalid_seq);

	zassert_true(
		ret == -ENOMEM,
		"adc_read() should return -ENOMEM,"
		" got unexpected value of %d",
		ret
	);
}

/**
 * @brief test adc_channel_setup() with invalid reference value
 *
 * function should return -EINVAL
 */

ZTEST(adc_error_cases, test_adc_setup_invalid_reference)
{
	int ret;

	struct adc_channel_cfg invalid_channel_cfg = VALID_CHANNEL->channel_cfg;
	/* set invalid reference */
	invalid_channel_cfg.reference = 99;

	ret = adc_channel_setup(VALID_CHANNEL->dev, &invalid_channel_cfg);

	zassert_true(
		ret == -EINVAL,
		"adc_channel_setup() should return -EINVAL,"
		" got unexpected value of %d",
		ret
	);
}

/**
 * @brief test adc_read() with invalid gain value
 *
 * function should return -EINVAL
 */

ZTEST(adc_error_cases, test_adc_setup_invalid_gain)
{
	int ret;

	struct adc_channel_cfg invalid_channel_cfg = VALID_CHANNEL->channel_cfg;
	/* set invalid gain value */
	invalid_channel_cfg.gain = 99;
	ret = adc_channel_setup(VALID_CHANNEL->dev, &invalid_channel_cfg);
	zassert_true(
		ret == -EINVAL,
		"adc_channel_setup() should return -EINVAL,"
		" got unexpected value of %d",
		ret
	);
}

static void *suite_setup(void)
{
	TC_PRINT("Test executed on %s\n", CONFIG_BOARD_TARGET);
	TC_PRINT("===================================================================\n");

	zassert_true(adc_is_ready_dt(VALID_CHANNEL), "ADC device is not ready");

	/* The sequence the board's first channel is valid for. */
	(void)adc_sequence_init_dt(VALID_CHANNEL, &valid_seq);

	/* A channel id below the width of the channel mask that no channel uses. */
	for (unused_channel_id = 0; unused_channel_id < 32; unused_channel_id++) {
		bool used = false;

		for (size_t i = 0; i < ADC_TEST_CHANNEL_COUNT; i++) {
			if (adc_test_channels[i].dev == VALID_CHANNEL->dev &&
			    adc_test_channels[i].channel_id == unused_channel_id) {
				used = true;
			}
		}
		if (!used) {
			break;
		}
	}
	zassert_true(unused_channel_id < 32, "Every channel id is in use");

	return NULL;
}

ZTEST_SUITE(adc_error_cases, NULL, suite_setup, NULL, NULL, NULL);
```
